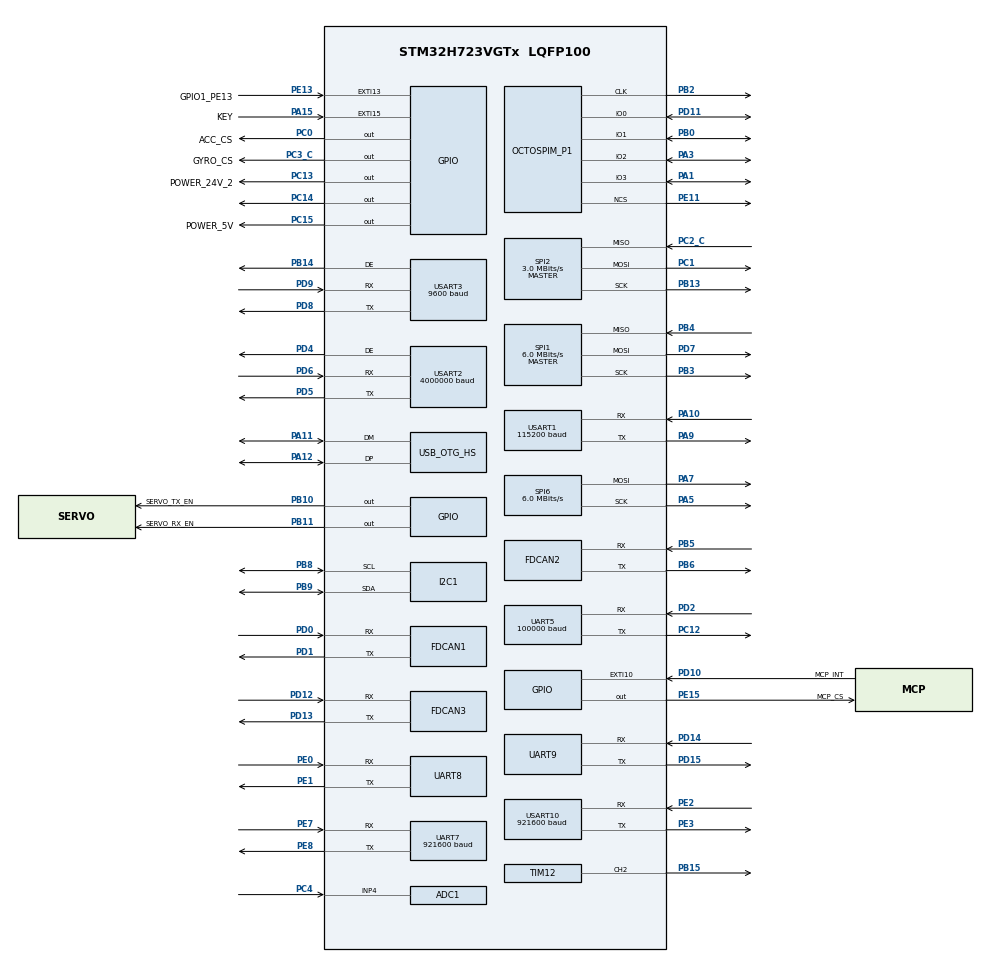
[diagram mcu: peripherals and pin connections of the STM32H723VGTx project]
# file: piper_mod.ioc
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ADC1.Channel-0\#ChannelRegularConversion=ADC_CHANNEL_4
ADC1.ClockPrescaler=ADC_CLOCK_ASYNC_DIV64
ADC1.ContinuousConvMode=ENABLE
ADC1.ConversionDataManagement=ADC_CONVERSIONDATA_DMA_CIRCULAR
ADC1.NbrOfConversion=1
ADC1.NbrOfConversionFlag=1
ADC1.OffsetNumber-0\#ChannelRegularConversion=ADC_OFFSET_NONE
ADC1.OffsetSignedSaturation-0\#ChannelRegularConversion=DISABLE
ADC1.Rank-0\#ChannelRegularConversion=1
ADC1.SamplingTime-0\#ChannelRegularConversion=ADC_SAMPLETIME_32CYCLES_5
ADC1.master=1
CORTEX_M7.AccessPermission-Cortex_Memory_Protection_Unit_Region0_Settings=MPU_REGION_PRIV_RO
CORTEX_M7.AccessPermission-Cortex_Memory_Protection_Unit_Region1_Settings=MPU_REGION_FULL_ACCESS
CORTEX_M7.AccessPermission-Cortex_Memory_Protection_Unit_Region2_Settings=MPU_REGION_FULL_ACCESS
CORTEX_M7.BaseAddress-Cortex_Memory_Protection_Unit_Region0_Settings=0x08000000
CORTEX_M7.BaseAddress-Cortex_Memory_Protection_Unit_Region1_Settings=0x20000000
CORTEX_M7.BaseAddress-Cortex_Memory_Protection_Unit_Region2_Settings=0x24000000
CORTEX_M7.CPU_DCache=Disabled
CORTEX_M7.CPU_ICache=Enabled
CORTEX_M7.Enable-Cortex_Memory_Protection_Unit_Region0_Settings=MPU_REGION_ENABLE
CORTEX_M7.Enable-Cortex_Memory_Protection_Unit_Region1_Settings=MPU_REGION_ENABLE
CORTEX_M7.Enable-Cortex_Memory_Protection_Unit_Region2_Settings=MPU_REGION_ENABLE
CORTEX_M7.IsBufferable-Cortex_Memory_Protection_Unit_Region1_Settings=MPU_ACCESS_BUFFERABLE
CORTEX_M7.IsCacheable-Cortex_Memory_Protection_Unit_Region0_Settings=MPU_ACCESS_CACHEABLE
CORTEX_M7.IsCacheable-Cortex_Memory_Protection_Unit_Region1_Settings=MPU_ACCESS_CACHEABLE
CORTEX_M7.IsShareable-Cortex_Memory_Protection_Unit_Region1_Settings=MPU_ACCESS_SHAREABLE
CORTEX_M7.IsShareable-Cortex_Memory_Protection_Unit_Region2_Settings=MPU_ACCESS_SHAREABLE
CORTEX_M7.MPU_Control=MPU_PRIVILEGED_DEFAULT
CORTEX_M7.Number-Cortex_Memory_Protection_Unit_Region1_Settings=MPU_REGION_NUMBER1
CORTEX_M7.Number-Cortex_Memory_Protection_Unit_Region2_Settings=MPU_REGION_NUMBER2
CORTEX_M7.Size-Cortex_Memory_Protection_Unit_Region0_Settings=MPU_REGION_SIZE_1MB
CORTEX_M7.Size-Cortex_Memory_Protection_Unit_Region1_Settings=MPU_REGION_SIZE_128KB
CORTEX_M7.Size-Cortex_Memory_Protection_Unit_Region2_Settings=MPU_REGION_SIZE_128KB
CORTEX_M7.TypeExtField-Cortex_Memory_Protection_Unit_Region0_Settings=MPU_TEX_LEVEL1
CORTEX_M7.TypeExtField-Cortex_Memory_Protection_Unit_Region1_Settings=MPU_TEX_LEVEL1
CORTEX_M7.TypeExtField-Cortex_Memory_Protection_Unit_Region2_Settings=MPU_TEX_LEVEL1
CRC.InputDataInversionMode=CRC_INPUTDATA_INVERSION_BYTE
CRC.OutputDataInversionMode=CRC_OUTPUTDATA_INVERSION_ENABLE
Dma.ADC1.7.Direction=DMA_PERIPH_TO_MEMORY
Dma.ADC1.7.EventEnable=DISABLE
Dma.ADC1.7.FIFOMode=DMA_FIFOMODE_DISABLE
Dma.ADC1.7.Instance=DMA1_Stream7
Dma.ADC1.7.MemDataAlignment=DMA_MDATAALIGN_HALFWORD
Dma.ADC1.7.MemInc=DMA_MINC_ENABLE
Dma.ADC1.7.Mode=DMA_CIRCULAR
Dma.ADC1.7.PeriphDataAlignment=DMA_PDATAALIGN_HALFWORD
Dma.ADC1.7.PeriphInc=DMA_PINC_DISABLE
Dma.ADC1.7.Polarity=HAL_DMAMUX_REQ_GEN_RISING
Dma.ADC1.7.Priority=DMA_PRIORITY_LOW
Dma.ADC1.7.RequestNumber=1
Dma.ADC1.7.SignalID=NONE
Dma.ADC1.7.SyncEnable=DISABLE
Dma.ADC1.7.SyncPolarity=HAL_DMAMUX_SYNC_NO_EVENT
Dma.ADC1.7.SyncRequestNumber=1
Dma.ADC1.7.SyncSignalID=NONE
Dma.Request0=SPI2_RX
Dma.Request1=SPI2_TX
Dma.Request10=USART3_TX
Dma.Request2=UART5_RX
Dma.Request3=UART7_RX
Dma.Request4=UART7_TX
Dma.Request5=USART10_RX
Dma.Request6=USART10_TX
Dma.Request7=ADC1
Dma.Request8=USART1_RX
Dma.Request9=USART3_RX
Dma.SPI2_RX.0.Direction=DMA_PERIPH_TO_MEMORY
Dma.SPI2_RX.0.EventEnable=DISABLE
Dma.SPI2_RX.0.FIFOMode=DMA_FIFOMODE_DISABLE
Dma.SPI2_RX.0.Instance=DMA1_Stream1
Dma.SPI2_RX.0.MemDataAlignment=DMA_MDATAALIGN_BYTE
Dma.SPI2_RX.0.MemInc=DMA_MINC_ENABLE
Dma.SPI2_RX.0.Mode=DMA_NORMAL
Dma.SPI2_RX.0.PeriphDataAlignment=DMA_PDATAALIGN_BYTE
Dma.SPI2_RX.0.PeriphInc=DMA_PINC_DISABLE
Dma.SPI2_RX.0.Polarity=HAL_DMAMUX_REQ_GEN_RISING
Dma.SPI2_RX.0.Priority=DMA_PRIORITY_VERY_HIGH
Dma.SPI2_RX.0.RequestNumber=1
Dma.SPI2_RX.0.SignalID=NONE
Dma.SPI2_RX.0.SyncEnable=DISABLE
Dma.SPI2_RX.0.SyncPolarity=HAL_DMAMUX_SYNC_NO_EVENT
Dma.SPI2_RX.0.SyncRequestNumber=1
Dma.SPI2_RX.0.SyncSignalID=NONE
Dma.SPI2_TX.1.Direction=DMA_MEMORY_TO_PERIPH
Dma.SPI2_TX.1.EventEnable=DISABLE
Dma.SPI2_TX.1.FIFOMode=DMA_FIFOMODE_DISABLE
Dma.SPI2_TX.1.Instance=DMA1_Stream2
Dma.SPI2_TX.1.MemDataAlignment=DMA_MDATAALIGN_BYTE
Dma.SPI2_TX.1.MemInc=DMA_MINC_ENABLE
Dma.SPI2_TX.1.Mode=DMA_NORMAL
Dma.SPI2_TX.1.PeriphDataAlignment=DMA_PDATAALIGN_BYTE
Dma.SPI2_TX.1.PeriphInc=DMA_PINC_DISABLE
Dma.SPI2_TX.1.Polarity=HAL_DMAMUX_REQ_GEN_RISING
Dma.SPI2_TX.1.Priority=DMA_PRIORITY_HIGH
Dma.SPI2_TX.1.RequestNumber=1
Dma.SPI2_TX.1.SignalID=NONE
Dma.SPI2_TX.1.SyncEnable=DISABLE
Dma.SPI2_TX.1.SyncPolarity=HAL_DMAMUX_SYNC_NO_EVENT
Dma.SPI2_TX.1.SyncRequestNumber=1
Dma.SPI2_TX.1.SyncSignalID=NONE
Dma.UART5_RX.2.Direction=DMA_PERIPH_TO_MEMORY
Dma.UART5_RX.2.EventEnable=DISABLE
Dma.UART5_RX.2.FIFOMode=DMA_FIFOMODE_DISABLE
Dma.UART5_RX.2.Instance=DMA1_Stream0
Dma.UART5_RX.2.MemDataAlignment=DMA_MDATAALIGN_BYTE
Dma.UART5_RX.2.MemInc=DMA_MINC_ENABLE
Dma.UART5_RX.2.Mode=DMA_NORMAL
Dma.UART5_RX.2.PeriphDataAlignment=DMA_PDATAALIGN_BYTE
Dma.UART5_RX.2.PeriphInc=DMA_PINC_DISABLE
Dma.UART5_RX.2.Polarity=HAL_DMAMUX_REQ_GEN_RISING
Dma.UART5_RX.2.Priority=DMA_PRIORITY_HIGH
Dma.UART5_RX.2.RequestNumber=1
Dma.UART5_RX.2.SignalID=NONE
Dma.UART5_RX.2.SyncEnable=DISABLE
Dma.UART5_RX.2.SyncPolarity=HAL_DMAMUX_SYNC_NO_EVENT
Dma.UART5_RX.2.SyncRequestNumber=1
Dma.UART5_RX.2.SyncSignalID=NONE
Dma.UART7_RX.3.Direction=DMA_PERIPH_TO_MEMORY
Dma.UART7_RX.3.EventEnable=DISABLE
Dma.UART7_RX.3.FIFOMode=DMA_FIFOMODE_DISABLE
Dma.UART7_RX.3.Instance=DMA1_Stream3
Dma.UART7_RX.3.MemDataAlignment=DMA_MDATAALIGN_BYTE
Dma.UART7_RX.3.MemInc=DMA_MINC_ENABLE
Dma.UART7_RX.3.Mode=DMA_NORMAL
Dma.UART7_RX.3.PeriphDataAlignment=DMA_PDATAALIGN_BYTE
Dma.UART7_RX.3.PeriphInc=DMA_PINC_DISABLE
Dma.UART7_RX.3.Polarity=HAL_DMAMUX_REQ_GEN_RISING
Dma.UART7_RX.3.Priority=DMA_PRIORITY_LOW
Dma.UART7_RX.3.RequestNumber=1
Dma.UART7_RX.3.SignalID=NONE
Dma.UART7_RX.3.SyncEnable=DISABLE
Dma.UART7_RX.3.SyncPolarity=HAL_DMAMUX_SYNC_NO_EVENT
Dma.UART7_RX.3.SyncRequestNumber=1
Dma.UART7_RX.3.SyncSignalID=NONE
Dma.UART7_TX.4.Direction=DMA_MEMORY_TO_PERIPH
Dma.UART7_TX.4.EventEnable=DISABLE
Dma.UART7_TX.4.FIFOMode=DMA_FIFOMODE_DISABLE
Dma.UART7_TX.4.Instance=DMA1_Stream4
Dma.UART7_TX.4.MemDataAlignment=DMA_MDATAALIGN_BYTE
Dma.UART7_TX.4.MemInc=DMA_MINC_ENABLE
Dma.UART7_TX.4.Mode=DMA_NORMAL
Dma.UART7_TX.4.PeriphDataAlignment=DMA_PDATAALIGN_BYTE
Dma.UART7_TX.4.PeriphInc=DMA_PINC_DISABLE
Dma.UART7_TX.4.Polarity=HAL_DMAMUX_REQ_GEN_RISING
Dma.UART7_TX.4.Priority=DMA_PRIORITY_LOW
Dma.UART7_TX.4.RequestNumber=1
Dma.UART7_TX.4.SignalID=NONE
Dma.UART7_TX.4.SyncEnable=DISABLE
Dma.UART7_TX.4.SyncPolarity=HAL_DMAMUX_SYNC_NO_EVENT
Dma.UART7_TX.4.SyncRequestNumber=1
Dma.UART7_TX.4.SyncSignalID=NONE
Dma.USART10_RX.5.Direction=DMA_PERIPH_TO_MEMORY
Dma.USART10_RX.5.EventEnable=DISABLE
Dma.USART10_RX.5.FIFOMode=DMA_FIFOMODE_DISABLE
Dma.USART10_RX.5.Instance=DMA1_Stream5
Dma.USART10_RX.5.MemDataAlignment=DMA_MDATAALIGN_BYTE
Dma.USART10_RX.5.MemInc=DMA_MINC_ENABLE
Dma.USART10_RX.5.Mode=DMA_NORMAL
Dma.USART10_RX.5.PeriphDataAlignment=DMA_PDATAALIGN_BYTE
Dma.USART10_RX.5.PeriphInc=DMA_PINC_DISABLE
Dma.USART10_RX.5.Polarity=HAL_DMAMUX_REQ_GEN_RISING
Dma.USART10_RX.5.Priority=DMA_PRIORITY_LOW
Dma.USART10_RX.5.RequestNumber=1
Dma.USART10_RX.5.SignalID=NONE
Dma.USART10_RX.5.SyncEnable=DISABLE
Dma.USART10_RX.5.SyncPolarity=HAL_DMAMUX_SYNC_NO_EVENT
Dma.USART10_RX.5.SyncRequestNumber=1
Dma.USART10_RX.5.SyncSignalID=NONE
Dma.USART10_TX.6.Direction=DMA_MEMORY_TO_PERIPH
Dma.USART10_TX.6.EventEnable=DISABLE
Dma.USART10_TX.6.FIFOMode=DMA_FIFOMODE_DISABLE
Dma.USART10_TX.6.Instance=DMA1_Stream6
Dma.USART10_TX.6.MemDataAlignment=DMA_MDATAALIGN_BYTE
Dma.USART10_TX.6.MemInc=DMA_MINC_ENABLE
Dma.USART10_TX.6.Mode=DMA_NORMAL
Dma.USART10_TX.6.PeriphDataAlignment=DMA_PDATAALIGN_BYTE
Dma.USART10_TX.6.PeriphInc=DMA_PINC_DISABLE
Dma.USART10_TX.6.Polarity=HAL_DMAMUX_REQ_GEN_RISING
Dma.USART10_TX.6.Priority=DMA_PRIORITY_LOW
Dma.USART10_TX.6.RequestNumber=1
Dma.USART10_TX.6.SignalID=NONE
Dma.USART10_TX.6.SyncEnable=DISABLE
Dma.USART10_TX.6.SyncPolarity=HAL_DMAMUX_SYNC_NO_EVENT
Dma.USART10_TX.6.SyncRequestNumber=1
Dma.USART10_TX.6.SyncSignalID=NONE
Dma.USART1_RX.8.Direction=DMA_PERIPH_TO_MEMORY
Dma.USART1_RX.8.EventEnable=DISABLE
Dma.USART1_RX.8.FIFOMode=DMA_FIFOMODE_DISABLE
Dma.USART1_RX.8.Instance=DMA2_Stream0
Dma.USART1_RX.8.MemDataAlignment=DMA_MDATAALIGN_BYTE
Dma.USART1_RX.8.MemInc=DMA_MINC_ENABLE
Dma.USART1_RX.8.Mode=DMA_NORMAL
Dma.USART1_RX.8.PeriphDataAlignment=DMA_PDATAALIGN_BYTE
Dma.USART1_RX.8.PeriphInc=DMA_PINC_DISABLE
Dma.USART1_RX.8.Polarity=HAL_DMAMUX_REQ_GEN_RISING
Dma.USART1_RX.8.Priority=DMA_PRIORITY_LOW
Dma.USART1_RX.8.RequestNumber=1
Dma.USART1_RX.8.SignalID=NONE
Dma.USART1_RX.8.SyncEnable=DISABLE
Dma.USART1_RX.8.SyncPolarity=HAL_DMAMUX_SYNC_NO_EVENT
Dma.USART1_RX.8.SyncRequestNumber=1
Dma.USART1_RX.8.SyncSignalID=NONE
Dma.USART3_RX.9.Direction=DMA_PERIPH_TO_MEMORY
Dma.USART3_RX.9.EventEnable=DISABLE
Dma.USART3_RX.9.FIFOMode=DMA_FIFOMODE_DISABLE
Dma.USART3_RX.9.Instance=DMA2_Stream2
Dma.USART3_RX.9.MemDataAlignment=DMA_MDATAALIGN_BYTE
Dma.USART3_RX.9.MemInc=DMA_MINC_ENABLE
Dma.USART3_RX.9.Mode=DMA_NORMAL
Dma.USART3_RX.9.PeriphDataAlignment=DMA_PDATAALIGN_BYTE
Dma.USART3_RX.9.PeriphInc=DMA_PINC_DISABLE
Dma.USART3_RX.9.Polarity=HAL_DMAMUX_REQ_GEN_RISING
Dma.USART3_RX.9.Priority=DMA_PRIORITY_LOW
Dma.USART3_RX.9.RequestNumber=1
Dma.USART3_RX.9.SignalID=NONE
Dma.USART3_RX.9.SyncEnable=DISABLE
Dma.USART3_RX.9.SyncPolarity=HAL_DMAMUX_SYNC_NO_EVENT
Dma.USART3_RX.9.SyncRequestNumber=1
Dma.USART3_RX.9.SyncSignalID=NONE
Dma.USART3_TX.10.Direction=DMA_MEMORY_TO_PERIPH
Dma.USART3_TX.10.EventEnable=DISABLE
Dma.USART3_TX.10.FIFOMode=DMA_FIFOMODE_DISABLE
Dma.USART3_TX.10.Instance=DMA2_Stream3
Dma.USART3_TX.10.MemDataAlignment=DMA_MDATAALIGN_BYTE
Dma.USART3_TX.10.MemInc=DMA_MINC_ENABLE
Dma.USART3_TX.10.Mode=DMA_NORMAL
Dma.USART3_TX.10.PeriphDataAlignment=DMA_PDATAALIGN_BYTE
Dma.USART3_TX.10.PeriphInc=DMA_PINC_DISABLE
Dma.USART3_TX.10.Polarity=HAL_DMAMUX_REQ_GEN_RISING
Dma.USART3_TX.10.Priority=DMA_PRIORITY_LOW
Dma.USART3_TX.10.RequestNumber=1
Dma.USART3_TX.10.SignalID=NONE
Dma.USART3_TX.10.SyncEnable=DISABLE
Dma.USART3_TX.10.SyncPolarity=HAL_DMAMUX_SYNC_NO_EVENT
Dma.USART3_TX.10.SyncRequestNumber=1
Dma.USART3_TX.10.SyncSignalID=NONE
FDCAN1.AutoRetransmission=DISABLE
FDCAN1.CalculateBaudRateNominal=1000000
FDCAN1.CalculateTimeBitNominal=1000
FDCAN1.CalculateTimeQuantumNominal=83.33333333333333
FDCAN1.DataPrescaler=2
FDCAN1.DataSyncJumpWidth=13
FDCAN1.DataTimeSeg1=1
FDCAN1.DataTimeSeg2=1
FDCAN1.ExtFiltersNbr=4
FDCAN1.NominalPrescaler=8
FDCAN1.NominalSyncJumpWidth=1
FDCAN1.NominalTimeSeg1=4
FDCAN1.NominalTimeSeg2=7
FDCAN1.ProtocolException=ENABLE
FDCAN1.RxBuffersNbr=2
FDCAN1.RxFifo0ElmtsNbr=8
FDCAN1.RxFifo1ElmtsNbr=8
FDCAN1.StdFiltersNbr=4
FDCAN1.TxBuffersNbr=8
FDCAN1.TxEventsNbr=8
FDCAN1.TxFifoQueueElmtsNbr=8
FDCAN2.CalculateBaudRateNominal=1000000
FDCAN2.CalculateTimeBitNominal=1000
FDCAN2.CalculateTimeQuantumNominal=83.33333333333333
FDCAN2.DataPrescaler=2
FDCAN2.DataSyncJumpWidth=13
FDCAN2.ExtFiltersNbr=4
FDCAN2.MessageRAMOffset=0x406
FDCAN2.NominalPrescaler=8
FDCAN2.NominalTimeSeg1=4
FDCAN2.NominalTimeSeg2=7
FDCAN2.RxBuffersNbr=2
FDCAN2.RxFifo0ElmtsNbr=8
FDCAN2.RxFifo1ElmtsNbr=8
FDCAN2.StdFiltersNbr=4
FDCAN2.TxBuffersNbr=8
FDCAN2.TxEventsNbr=8
FDCAN2.TxFifoQueueElmtsNbr=8
FDCAN3.AutoRetransmission=DISABLE
FDCAN3.CalculateBaudRateNominal=1000000
FDCAN3.CalculateTimeBitNominal=1000
FDCAN3.CalculateTimeQuantumNominal=62.5
FDCAN3.DataPrescaler=3
FDCAN3.DataSyncJumpWidth=2
FDCAN3.DataTimeSeg1=7
FDCAN3.DataTimeSeg2=2
FDCAN3.ExtFiltersNbr=0
FDCAN3.FrameFormat=FDCAN_FRAME_FD_BRS
FDCAN3.MessageRAMOffset=0x812
FDCAN3.NominalPrescaler=6
FDCAN3.NominalSyncJumpWidth=2
FDCAN3.NominalTimeSeg1=13
FDCAN3.NominalTimeSeg2=2
FDCAN3.RxBufferSize=FDCAN_DATA_BYTES_64
FDCAN3.RxFifo0ElmtSize=FDCAN_DATA_BYTES_64
FDCAN3.RxFifo0ElmtsNbr=16
FDCAN3.RxFifo1ElmtSize=FDCAN_DATA_BYTES_64
FDCAN3.StdFiltersNbr=0
FDCAN3.TxBuffersNbr=1
FDCAN3.TxElmtSize=FDCAN_DATA_BYTES_64
FDCAN3.TxFifoQueueElmtsNbr=8
FDCAN3.TxFifoQueueMode=FDCAN_TX_FIFO_OPERATION
I2C1.Timing=0x60404E72
Mcu.Family=STM32H7
Mcu.Name=STM32H723VGTx
Mcu.Package=LQFP100
NVIC.DMA1_Stream0_IRQn=true\:4\:0\:true\:false\:true\:false\:true\:true
NVIC.DMA1_Stream1_IRQn=true\:5\:0\:true\:false\:true\:false\:true\:true
NVIC.DMA1_Stream2_IRQn=true\:5\:0\:true\:false\:true\:false\:true\:true
NVIC.DMA1_Stream3_IRQn=true\:6\:0\:true\:false\:true\:false\:true\:true
NVIC.DMA1_Stream4_IRQn=true\:0\:0\:false\:false\:true\:false\:true\:true
NVIC.DMA1_Stream5_IRQn=true\:0\:0\:false\:false\:true\:false\:true\:true
NVIC.DMA1_Stream6_IRQn=true\:0\:0\:false\:false\:true\:false\:true\:true
NVIC.DMA1_Stream7_IRQn=true\:0\:0\:false\:false\:true\:false\:true\:true
NVIC.DMA2_Stream0_IRQn=true\:0\:0\:false\:false\:true\:false\:true\:true
NVIC.DMA2_Stream2_IRQn=true\:0\:0\:false\:false\:true\:false\:true\:true
NVIC.DMA2_Stream3_IRQn=true\:0\:0\:false\:false\:true\:false\:true\:true
NVIC.EXTI15_10_IRQn=true\:4\:0\:true\:false\:true\:true\:true\:true
NVIC.FDCAN1_IT0_IRQn=true\:5\:0\:true\:false\:true\:true\:true\:true
NVIC.FDCAN2_IT0_IRQn=true\:5\:0\:true\:false\:true\:true\:true\:true
NVIC.FDCAN3_IT0_IRQn=true\:6\:0\:true\:false\:true\:true\:true\:true
NVIC.OTG_HS_IRQn=true\:0\:0\:false\:false\:true\:false\:true\:true
NVIC.PriorityGroup=NVIC_PRIORITYGROUP_4
NVIC.SPI2_IRQn=true\:5\:0\:true\:false\:true\:false\:true\:true
NVIC.TIM8_UP_TIM13_IRQn=true\:6\:0\:true\:false\:true\:true\:true\:true
NVIC.UART5_IRQn=true\:4\:0\:true\:false\:true\:true\:true\:true
NVIC.UART7_IRQn=true\:6\:0\:true\:false\:true\:true\:true\:true
NVIC.USART10_IRQn=true\:0\:0\:false\:false\:true\:true\:true\:true
NVIC.USART1_IRQn=true\:0\:0\:false\:false\:true\:true\:true\:true
NVIC.USART2_IRQn=true\:0\:0\:false\:false\:true\:true\:true\:true
NVIC.USART3_IRQn=true\:0\:0\:false\:false\:true\:true\:true\:true
OCTOSPI2.ClockMode=HAL_OSPI_CLOCK_MODE_3
OCTOSPI2.ClockPrescaler=3
OCTOSPI2.DeviceSize=23
OCTOSPI2.FifoThreshold=8
OCTOSPI2.SampleShifting=HAL_OSPI_SAMPLE_SHIFTING_HALFCYCLE
PA1.Mode=OCTOSPI2_IOL_Port1L
PA1.Signal=OCTOSPIM_P1_IO3
PA10.Mode=Asynchronous
PA10.Signal=USART1_RX
PA11.Mode=Device_Only_FS
PA11.Signal=USB_OTG_HS_DM
PA12.Mode=Device_Only_FS
PA12.Signal=USB_OTG_HS_DP
PA13(JTMS/SWDIO).Mode=Serial_Wire
PA13(JTMS/SWDIO).Signal=DEBUG_JTMS-SWDIO
PA14(JTCK/SWCLK).Mode=Serial_Wire
PA14(JTCK/SWCLK).Signal=DEBUG_JTCK-SWCLK
PA15(JTDI).GPIO_Label=KEY
PA15(JTDI).GPIO_PuPd=GPIO_NOPULL
PA15(JTDI).Signal=GPXTI15
PA3.Mode=OCTOSPI2_IOL_Port1L
PA3.Signal=OCTOSPIM_P1_IO2
PA5.Mode=TX_Only_Simplex_Unidirect_Master
PA5.Signal=SPI6_SCK
PA7.Mode=TX_Only_Simplex_Unidirect_Master
PA7.Signal=SPI6_MOSI
PA9.Mode=Asynchronous
PA9.Signal=USART1_TX
PB0.Mode=OCTOSPI2_IOL_Port1L
PB0.Signal=OCTOSPIM_P1_IO1
PB10.GPIO_Label=SERVO_TX_EN
PB10.Signal=GPIO_Output
PB11.GPIO_Label=SERVO_RX_EN
PB11.Signal=GPIO_Output
PB13.GPIO_Speed=GPIO_SPEED_FREQ_VERY_HIGH
PB13.Mode=Full_Duplex_Master
PB13.Signal=SPI2_SCK
PB14.Mode=Hardware Flow Control (RS485)
PB14.Signal=USART3_DE
PB15.Signal=S_TIM12_CH2
PB2.Mode=O2_P1_CLK
PB2.Signal=OCTOSPIM_P1_CLK
PB3(JTDO/TRACESWO).Mode=Full_Duplex_Master
PB3(JTDO/TRACESWO).Signal=SPI1_SCK
PB4(NJTRST).Mode=Full_Duplex_Master
PB4(NJTRST).Signal=SPI1_MISO
PB5.Mode=FDCAN_Activate
PB5.Signal=FDCAN2_RX
PB6.GPIO_FM6=__NULL
PB6.GPIO_Speed=GPIO_SPEED_FREQ_LOW
PB6.Mode=FDCAN_Activate
PB6.Signal=FDCAN2_TX
PB8.Mode=I2C
PB8.Signal=I2C1_SCL
PB9.Mode=I2C
PB9.Signal=I2C1_SDA
PC0.GPIO_Label=ACC_CS
PC0.GPIO_Speed=GPIO_SPEED_FREQ_VERY_HIGH
PC0.PinState=GPIO_PIN_SET
PC0.Signal=GPIO_Output
PC1.GPIO_Speed=GPIO_SPEED_FREQ_VERY_HIGH
PC1.Mode=Full_Duplex_Master
PC1.Signal=SPI2_MOSI
PC12.GPIO_Speed=GPIO_SPEED_FREQ_LOW
PC12.Mode=Asynchronous
PC12.Signal=UART5_TX
PC13.GPIO_Label=POWER_24V_2
PC13.PinState=GPIO_PIN_SET
PC13.Signal=GPIO_Output
PC14-OSC32_IN.Signal=GPIO_Output
PC15-OSC32_OUT.GPIO_Label=POWER_5V
PC15-OSC32_OUT.PinState=GPIO_PIN_SET
PC15-OSC32_OUT.Signal=GPIO_Output
PC2_C.GPIO_Speed=GPIO_SPEED_FREQ_VERY_HIGH
PC2_C.Mode=Full_Duplex_Master
PC2_C.Signal=SPI2_MISO
PC3_C.GPIO_Label=GYRO_CS
PC3_C.GPIO_Speed=GPIO_SPEED_FREQ_VERY_HIGH
PC3_C.PinState=GPIO_PIN_SET
PC3_C.Signal=GPIO_Output
PC4.Signal=ADCx_INP4
PD0.GPIO_Speed=GPIO_SPEED_FREQ_LOW
PD0.Mode=FDCAN_Activate
PD0.Signal=FDCAN1_RX
PD1.GPIO_Speed=GPIO_SPEED_FREQ_LOW
PD1.Mode=FDCAN_Activate
PD1.Signal=FDCAN1_TX
PD10.GPIO_Label=MCP_INT
PD10.GPIO_ModeDefaultEXTI=GPIO_MODE_IT_FALLING
PD10.GPIO_PuPd=GPIO_PULLUP
PD10.Signal=GPXTI10
PD11.Mode=OCTOSPI2_IOL_Port1L
PD11.Signal=OCTOSPIM_P1_IO0
PD12.GPIO_Speed=GPIO_SPEED_FREQ_LOW
PD12.Mode=FDCAN_Activate
PD12.Signal=FDCAN3_RX
PD13.GPIO_Speed=GPIO_SPEED_FREQ_LOW
PD13.Mode=FDCAN_Activate
PD13.Signal=FDCAN3_TX
PD14.Mode=Asynchronous
PD14.Signal=UART9_RX
PD15.Mode=Asynchronous
PD15.Signal=UART9_TX
PD2.GPIO_Speed=GPIO_SPEED_FREQ_LOW
PD2.Mode=Asynchronous
PD2.Signal=UART5_RX
PD4.Mode=Hardware Flow Control (RS485)
PD4.Signal=USART2_DE
PD5.Mode=Asynchronous
PD5.Signal=USART2_TX
PD6.Mode=Asynchronous
PD6.Signal=USART2_RX
PD7.Mode=Full_Duplex_Master
PD7.Signal=SPI1_MOSI
PD8.Mode=Asynchronous
PD8.Signal=USART3_TX
PD9.Mode=Asynchronous
PD9.Signal=USART3_RX
PE0.Mode=Asynchronous
PE0.Signal=UART8_RX
PE1.Mode=Asynchronous
PE1.Signal=UART8_TX
PE11.Mode=OCTOSPI2_Port1_NCS
PE11.Signal=OCTOSPIM_P1_NCS
PE13.GPIO_Label=GPIO1_PE13
PE13.GPIO_ModeDefaultEXTI=GPIO_MODE_IT_FALLING
PE13.Signal=GPXTI13
PE15.GPIO_Label=MCP_CS
PE15.Signal=GPIO_Output
PE2.Mode=Asynchronous
PE2.Signal=USART10_RX
PE3.Mode=Asynchronous
PE3.Signal=USART10_TX
PE7.Mode=Asynchronous
PE7.Signal=UART7_RX
PE8.Mode=Asynchronous
PE8.Signal=UART7_TX
PH0-OSC_IN.Mode=HSE-External-Oscillator
PH0-OSC_IN.Signal=RCC_OSC_IN
PH1-OSC_OUT.Mode=HSE-External-Oscillator
PH1-OSC_OUT.Signal=RCC_OSC_OUT
ProjectManager.HeapSize=0x1000
ProjectManager.StackSize=0x2000
ProjectManager.TargetToolchain=CMake
RCC.ADCFreq_Value=96000000
RCC.APB1Freq_Value=137500000
RCC.APB2Freq_Value=137500000
RCC.APB3Freq_Value=137500000
RCC.APB4Freq_Value=137500000
RCC.CortexFreq_Value=550000000
RCC.D1PPRE=RCC_APB3_DIV2
RCC.D2PPRE1=RCC_APB1_DIV2
RCC.D2PPRE2=RCC_APB2_DIV2
RCC.D3PPRE=RCC_APB4_DIV2
RCC.DIVM1=3
RCC.DIVM2=2
RCC.DIVN1=68
RCC.DIVN2=16
RCC.DIVP1=1
RCC.DIVQ1=3
RCC.FDCANCLockSelection=RCC_FDCANCLKSOURCE_PLL2
RCC.HCLKFreq_Value=275000000
RCC.HPRE=RCC_HCLK_DIV2
RCC.HSE_VALUE=24000000
RCC.PLL2FRACN=0
RCC.PLL3FRACN=0
RCC.PLLFRACN=6144
RCC.PLLSourceVirtual=RCC_PLLSOURCE_HSE
RCC.SPI123CLockSelection=RCC_SPI123CLKSOURCE_PLL2
RCC.SPI6CLockSelection=RCC_SPI6CLKSOURCE_HSE
RCC.SYSCLKFreq_VALUE=550000000
RCC.SYSCLKSource=RCC_SYSCLKSOURCE_PLLCLK
RCC.USART234578CLockSelection=RCC_USART234578CLKSOURCE_PLL2
RCC.USBCLockSelection=RCC_USBCLKSOURCE_HSI48
RCC.USBFreq_Value=48000000
SH.ADCx_INP4.0=ADC1_INP4,IN4-Single-Ended
SH.S_TIM12_CH2.0=TIM12_CH2,PWM Generation2 CH2
SPI1.BaudRatePrescaler=SPI_BAUDRATEPRESCALER_16
SPI1.CalculateBaudRate=6.0 MBits/s
SPI1.DataSize=SPI_DATASIZE_8BIT
SPI1.Direction=SPI_DIRECTION_2LINES
SPI1.Mode=SPI_MODE_MASTER
SPI1.VirtualType=VM_MASTER
SPI2.BaudRatePrescaler=SPI_BAUDRATEPRESCALER_32
SPI2.CLKPhase=SPI_PHASE_2EDGE
SPI2.CLKPolarity=SPI_POLARITY_HIGH
SPI2.CalculateBaudRate=3.0 MBits/s
SPI2.DataSize=SPI_DATASIZE_8BIT
SPI2.Direction=SPI_DIRECTION_2LINES
SPI2.Mode=SPI_MODE_MASTER
SPI2.VirtualType=VM_MASTER
SPI6.BaudRatePrescaler=SPI_BAUDRATEPRESCALER_4
SPI6.CLKPhase=SPI_PHASE_2EDGE
SPI6.CalculateBaudRate=6.0 MBits/s
SPI6.DataSize=SPI_DATASIZE_8BIT
SPI6.Direction=SPI_DIRECTION_2LINES_TXONLY
SPI6.Mode=SPI_MODE_MASTER
SPI6.VirtualType=VM_MASTER
TIM12.AutoReloadPreload=TIM_AUTORELOAD_PRELOAD_ENABLE
TIM12.Channel-PWM\ Generation2\ CH2=TIM_CHANNEL_2
TIM12.Period=1000-1
TIM12.Prescaler=275-1
TIM12.Pulse-PWM\ Generation2\ CH2=0
TIM13.Period=500-1
TIM13.Prescaler=275-1
UART5.BaudRate=100000
UART5.Mode=MODE_RX
UART5.OverrunDisableParam=UART_ADVFEATURE_OVERRUN_ENABLE
UART5.Parity=PARITY_EVEN
UART5.StopBits=UART_STOPBITS_2
UART5.WordLength=WORDLENGTH_9B
UART7.BaudRate=921600
USART1.BaudRate=115200
USART1.Mode=MODE_TX_RX
USART1.VirtualMode-Asynchronous=VM_ASYNC
USART1.WordLength=WORDLENGTH_8B
USART10.BaudRate=921600
USART10.VirtualMode=VM_ASYNC
USART2.BaudRate=4000000
USART2.OverSampling=UART_OVERSAMPLING_8
USART2.VirtualMode-Asynchronous=VM_ASYNC
USART2.VirtualMode-Hardware\ Flow\ Control\ (RS485)=VM_ASYNC
USART3.BaudRate=9600
USART3.VirtualMode-Asynchronous=VM_ASYNC
USART3.VirtualMode-Hardware\ Flow\ Control\ (RS485)=VM_ASYNC
USB_DEVICE.CLASS_NAME_HS=CDC
USB_DEVICE.VirtualMode=Cdc
USB_DEVICE.VirtualModeHS=Cdc_HS
USB_OTG_HS.VirtualMode-Device_Only_FS=Device_Only_FS
VP_CRC_VS_CRC.Mode=CRC_Activate
VP_MEMORYMAP_VS_MEMORYMAP.Mode=CurAppReg
VP_OCTOSPI2_VS_quad.Mode=quad_mode
VP_RNG_VS_RNG.Mode=RNG_Activate
VP_TIM13_VS_ClockSourceINT.Mode=Enable_Timer
VP_USB_DEVICE_VS_USB_DEVICE_CDC_HS.Mode=CDC_HS
board=custom

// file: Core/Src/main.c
/* USER CODE BEGIN Header */
/**
  ******************************************************************************
  * @file           : main.c
  * @brief          : Main program body
  ******************************************************************************
  * @attention
  *
  * Copyright (c) 2026 STMicroelectronics.
  * All rights reserved.
  *
  * This software is licensed under terms that can be found in the LICENSE file
  * in the root directory of this software component.
  * If no LICENSE file comes with this software, it is provided AS-IS.
  *
  ******************************************************************************
  */
/* USER CODE END Header */
#include "main.h"
#include "adc.h"
#include "dma.h"
#include "fdcan.h"
#include "i2c.h"
#include "rng.h"
#include "spi.h"
#include "tim.h"
#include "usart.h"
#include "usb_device.h"
#include "gpio.h"

void SystemClock_Config(void);
void PeriphCommonClock_Config(void);
static void MPU_Config(void);
/* USER CODE BEGIN PFP */
void AppMain(void);
/* USER CODE END PFP */

int main(void)
{

  /* MPU Configuration--------------------------------------------------------*/
  MPU_Config();

  /* Enable the CPU Cache */

  /* Enable I-Cache---------------------------------------------------------*/
  SCB_EnableICache();

  /* MCU Configuration--------------------------------------------------------*/

  /* Reset of all peripherals, Initializes the Flash interface and the Systick. */
  HAL_Init();

  /* Configure the system clock */
  SystemClock_Config();

  /* Configure the peripherals common clocks */
  PeriphCommonClock_Config();

  /* Initialize all configured peripherals */
  MX_GPIO_Init();
  MX_DMA_Init();
  MX_SPI2_Init();
  MX_FDCAN1_Init();
  MX_FDCAN2_Init();
  MX_FDCAN3_Init();
  MX_TIM12_Init();
  MX_SPI6_Init();
  MX_UART5_Init();
  MX_TIM13_Init();
  MX_RNG_Init();
  MX_USART1_UART_Init();
  MX_UART7_Init();
  MX_USART10_UART_Init();
  MX_USART2_UART_Init();
  MX_ADC1_Init();
  MX_SPI1_Init();
  MX_I2C1_Init();
  MX_UART8_Init();
  MX_UART9_Init();
  MX_USB_DEVICE_Init();
  MX_USART3_UART_Init();
  /* USER CODE BEGIN 2 */
  AppMain();
  /* USER CODE END 2 */

  /* Infinite loop */
  while (1)
  {

  }
}

void SystemClock_Config(void)
{
  RCC_OscInitTypeDef RCC_OscInitStruct = {0};
  RCC_ClkInitTypeDef RCC_ClkInitStruct = {0};

  /** Supply configuration update enable
  */
  HAL_PWREx_ConfigSupply(PWR_LDO_SUPPLY);

  /** Configure the main internal regulator output voltage
  */
  __HAL_PWR_VOLTAGESCALING_CONFIG(PWR_REGULATOR_VOLTAGE_SCALE0);

  while(!__HAL_PWR_GET_FLAG(PWR_FLAG_VOSRDY)) {}

  /** Initializes the RCC Oscillators according to the specified parameters
  * in the RCC_OscInitTypeDef structure.
  */
  RCC_OscInitStruct.OscillatorType = RCC_OSCILLATORTYPE_HSI48|RCC_OSCILLATORTYPE_HSE;
  RCC_OscInitStruct.HSEState = RCC_HSE_ON;
  RCC_OscInitStruct.HSI48State = RCC_HSI48_ON;
  RCC_OscInitStruct.PLL.PLLState = RCC_PLL_ON;
  RCC_OscInitStruct.PLL.PLLSource = RCC_PLLSOURCE_HSE;
  RCC_OscInitStruct.PLL.PLLM = 3;
  RCC_OscInitStruct.PLL.PLLN = 68;
  RCC_OscInitStruct.PLL.PLLP = 1;
  RCC_OscInitStruct.PLL.PLLQ = 3;
  RCC_OscInitStruct.PLL.PLLR = 2;
  RCC_OscInitStruct.PLL.PLLRGE = RCC_PLL1VCIRANGE_3;
  RCC_OscInitStruct.PLL.PLLVCOSEL = RCC_PLL1VCOWIDE;
  RCC_OscInitStruct.PLL.PLLFRACN = 6144;
  if (HAL_RCC_OscConfig(&RCC_OscInitStruct) != HAL_OK)
  {
    Error_Handler();
  }

  /** Initializes the CPU, AHB and APB buses clocks
  */
  RCC_ClkInitStruct.ClockType = RCC_CLOCKTYPE_HCLK|RCC_CLOCKTYPE_SYSCLK
                              |RCC_CLOCKTYPE_PCLK1|RCC_CLOCKTYPE_PCLK2
                              |RCC_CLOCKTYPE_D3PCLK1|RCC_CLOCKTYPE_D1PCLK1;
  RCC_ClkInitStruct.SYSCLKSource = RCC_SYSCLKSOURCE_PLLCLK;
  RCC_ClkInitStruct.SYSCLKDivider = RCC_SYSCLK_DIV1;
  RCC_ClkInitStruct.AHBCLKDivider = RCC_HCLK_DIV2;
  RCC_ClkInitStruct.APB3CLKDivider = RCC_APB3_DIV2;
  RCC_ClkInitStruct.APB1CLKDivider = RCC_APB1_DIV2;
  RCC_ClkInitStruct.APB2CLKDivider = RCC_APB2_DIV2;
  RCC_ClkInitStruct.APB4CLKDivider = RCC_APB4_DIV2;

  if (HAL_RCC_ClockConfig(&RCC_ClkInitStruct, FLASH_LATENCY_3) != HAL_OK)
  {
    Error_Handler();
  }
}

void PeriphCommonClock_Config(void)
{
  RCC_PeriphCLKInitTypeDef PeriphClkInitStruct = {0};

  /** Initializes the peripherals clock
  */
  PeriphClkInitStruct.PeriphClockSelection = RCC_PERIPHCLK_ADC|RCC_PERIPHCLK_SPI2
                              |RCC_PERIPHCLK_SPI1|RCC_PERIPHCLK_UART5
                              |RCC_PERIPHCLK_UART8|RCC_PERIPHCLK_FDCAN
                              |RCC_PERIPHCLK_UART7|RCC_PERIPHCLK_USART2
                              |RCC_PERIPHCLK_USART3;
  PeriphClkInitStruct.PLL2.PLL2M = 2;
  PeriphClkInitStruct.PLL2.PLL2N = 16;
  PeriphClkInitStruct.PLL2.PLL2P = 2;
  PeriphClkInitStruct.PLL2.PLL2Q = 2;
  PeriphClkInitStruct.PLL2.PLL2R = 2;
  PeriphClkInitStruct.PLL2.PLL2RGE = RCC_PLL2VCIRANGE_3;
  PeriphClkInitStruct.PLL2.PLL2VCOSEL = RCC_PLL2VCOWIDE;
  PeriphClkInitStruct.PLL2.PLL2FRACN = 0;
  PeriphClkInitStruct.Spi123ClockSelection = RCC_SPI123CLKSOURCE_PLL2;
  PeriphClkInitStruct.FdcanClockSelection = RCC_FDCANCLKSOURCE_PLL2;
  PeriphClkInitStruct.Usart234578ClockSelection = RCC_USART234578CLKSOURCE_PLL2;
  PeriphClkInitStruct.AdcClockSelection = RCC_ADCCLKSOURCE_PLL2;
  if (HAL_RCCEx_PeriphCLKConfig(&PeriphClkInitStruct) != HAL_OK)
  {
    Error_Handler();
  }
}

 /* MPU Configuration */

void MPU_Config(void)
{
  MPU_Region_InitTypeDef MPU_InitStruct = {0};

  /* Disables the MPU */
  HAL_MPU_Disable();

  /** Initializes and configures the Region and the memory to be protected
  */
  MPU_InitStruct.Enable = MPU_REGION_ENABLE;
  MPU_InitStruct.Number = MPU_REGION_NUMBER0;
  MPU_InitStruct.BaseAddress = 0x08000000;
  MPU_InitStruct.Size = MPU_REGION_SIZE_1MB;
  MPU_InitStruct.SubRegionDisable = 0x0;
  MPU_InitStruct.TypeExtField = MPU_TEX_LEVEL1;
  MPU_InitStruct.AccessPermission = MPU_REGION_PRIV_RO;
  MPU_InitStruct.DisableExec = MPU_INSTRUCTION_ACCESS_ENABLE;
  MPU_InitStruct.IsShareable = MPU_ACCESS_NOT_SHAREABLE;
  MPU_InitStruct.IsCacheable = MPU_ACCESS_CACHEABLE;
  MPU_InitStruct.IsBufferable = MPU_ACCESS_NOT_BUFFERABLE;

  HAL_MPU_ConfigRegion(&MPU_InitStruct);

  /** Initializes and configures the Region and the memory to be protected
  */
  MPU_InitStruct.Number = MPU_REGION_NUMBER1;
  MPU_InitStruct.BaseAddress = 0x20000000;
  MPU_InitStruct.Size = MPU_REGION_SIZE_128KB;
  MPU_InitStruct.AccessPermission = MPU_REGION_FULL_ACCESS;
  MPU_InitStruct.IsShareable = MPU_ACCESS_SHAREABLE;
  MPU_InitStruct.IsBufferable = MPU_ACCESS_BUFFERABLE;

  HAL_MPU_ConfigRegion(&MPU_InitStruct);

  /** Initializes and configures the Region and the memory to be protected
  */
  MPU_InitStruct.Number = MPU_REGION_NUMBER2;
  MPU_InitStruct.BaseAddress = 0x24000000;
  MPU_InitStruct.IsCacheable = MPU_ACCESS_NOT_CACHEABLE;
  MPU_InitStruct.IsBufferable = MPU_ACCESS_NOT_BUFFERABLE;

  HAL_MPU_ConfigRegion(&MPU_InitStruct);
  /* Enables the MPU */
  HAL_MPU_Enable(MPU_PRIVILEGED_DEFAULT);

}

void Error_Handler(void)
{
  __disable_irq();
  while (1)
  {
  }
}
